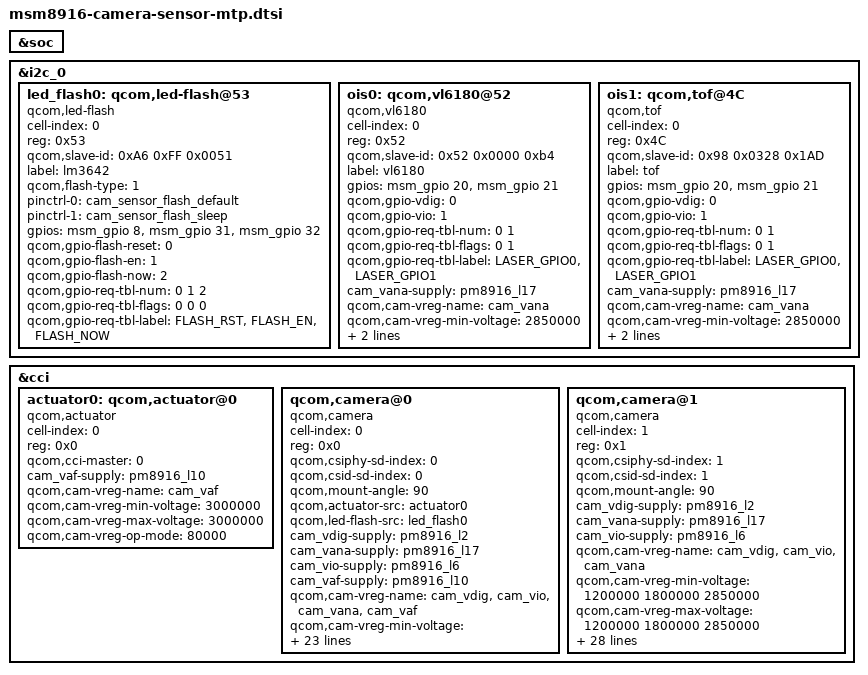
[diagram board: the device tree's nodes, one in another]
/*
 * Copyright (c) 2014, The Linux Foundation. All rights reserved.
 *
 * This program is free software; you can redistribute it and/or modify
 * it under the terms of the GNU General Public License version 2 and
 * only version 2 as published by the Free Software Foundation.
 *
 * This program is distributed in the hope that it will be useful,
 * but WITHOUT ANY WARRANTY; without even the implied warranty of
 * MERCHANTABILITY or FITNESS FOR A PARTICULAR PURPOSE.  See the
 * GNU General Public License for more details.
 */

&soc {
};

&i2c_0 {
//ASUS_BSP: Sam: flash driver i2c +++
	led_flash0: qcom,led-flash@53{
			cell-index = <0>;
			reg = <0x53>;
			qcom,slave-id = <0xA6 0xFF 0x0051>;
			compatible = "qcom,led-flash";
			label = "lm3642";
			//qcom,flash-name = "lm3642";
			qcom,flash-type = <1>;
			//qcom,enable_pinctrl;
			pinctrl-names = "cam_flash_default", "cam_flash_suspend";
			pinctrl-0 = <&cam_sensor_flash_default>;
			pinctrl-1 = <&cam_sensor_flash_sleep>;
			gpios = <&msm_gpio 8 0>,
				<&msm_gpio 31 0>,
				<&msm_gpio 32 0>;
			qcom,gpio-flash-reset = <0>;
			qcom,gpio-flash-en = <1>;
			qcom,gpio-flash-now = <2>;
			qcom,gpio-req-tbl-num = <0 1 2>;
			qcom,gpio-req-tbl-flags = <0 0 0>;
			qcom,gpio-req-tbl-label = "FLASH_RST",
				"FLASH_EN",
				"FLASH_NOW";
	};
//ASUS_BSP: Sam: flash driver i2c ---

//ASUS_BSP: Sam: laser driver i2c +++
       ois0: qcom,vl6180@52 {
		   cell-index = <0>;
		   reg = <0x52>;
		   qcom,slave-id = <0x52 0x0000 0xb4>;
		   compatible = "qcom,vl6180";
		   label = "vl6180";
/*
		   pinctrl-names = "laser_focus_default", "laser_focus_suspend";
		   pinctrl-0 = <&cam_sensor_laser_focus_gpio0_default &cam_sensor_laser_focus_gpio1_default >;
		   pinctrl-1 = <&cam_sensor_laser_focus_gpio0_sleep &cam_sensor_laser_focus_gpio1_sleep>;
*/
		   gpios = <&msm_gpio 20 0>,
				   <&msm_gpio 21 0>;//113 interrupt
		   qcom,gpio-vdig = <0>;
		   qcom,gpio-vio = <1>;
		   qcom,gpio-req-tbl-num = <0 1>;
		   qcom,gpio-req-tbl-flags = <0 1>;//GPIO0 pin configured as input, pull up, software not do anything with it
		   qcom,gpio-req-tbl-label = "LASER_GPIO0",
									 "LASER_GPIO1";
		   cam_vana-supply = <&pm8916_l17>;
		   qcom,cam-vreg-name = "cam_vana";
		   qcom,cam-vreg-min-voltage = <2850000>;
		   qcom,cam-vreg-max-voltage = <2850000>;
		   qcom,cam-vreg-op-mode = <80000>;
       };
//ASUS_BSP: Sam: laser driver i2c ---

		ois1: qcom,tof@4C {
			cell-index = <0>;
			reg = <0x4C>;
			qcom,slave-id = <0x98 0x0328 0x1AD>;
			compatible = "qcom,tof";
			label = "tof";
/*
		   pinctrl-names = "laser_focus_default", "laser_focus_suspend";
		   pinctrl-0 = <&cam_sensor_laser_focus_gpio0_default &cam_sensor_laser_focus_gpio1_default >;
		   pinctrl-1 = <&cam_sensor_laser_focus_gpio0_sleep &cam_sensor_laser_focus_gpio1_sleep>;
*/
		   gpios = <&msm_gpio 20 0>,
				   <&msm_gpio 21 0>;//113 interrupt
		   qcom,gpio-vdig = <0>;
		   qcom,gpio-vio = <1>;
		   qcom,gpio-req-tbl-num = <0 1>;
		   qcom,gpio-req-tbl-flags = <0 1>;//GPIO0 pin configured as input, pull up, software not do anything with it
		   qcom,gpio-req-tbl-label = "LASER_GPIO0",
									 "LASER_GPIO1";
		   cam_vana-supply = <&pm8916_l17>;
		   qcom,cam-vreg-name = "cam_vana";
		   qcom,cam-vreg-min-voltage = <2850000>;
		   qcom,cam-vreg-max-voltage = <2850000>;
		   qcom,cam-vreg-op-mode = <80000>;
		};
};

&cci {

	actuator0: qcom,actuator@0 {
		cell-index = <0>;
		reg = <0x0>;
		compatible = "qcom,actuator";
		qcom,cci-master = <0>;
		cam_vaf-supply = <&pm8916_l10>;
		qcom,cam-vreg-name = "cam_vaf";
		qcom,cam-vreg-min-voltage = <3000000>;
		qcom,cam-vreg-max-voltage = <3000000>;
		qcom,cam-vreg-op-mode = <80000>;
	};



/*
	eeprom0: qcom,eeprom@20 {
		cell-index = <0>;
		reg = <0x20>;
		qcom,eeprom-name = "sonyimx135";
		compatible = "qcom,eeprom";
		qcom,slave-addr = <0x20>;
		qcom,cci-master = <0>;
		qcom,num-blocks = <16>;

		qcom,page0 = <1 0x3b02 2 0x10 1 5>;
		qcom,pageen0 = <1 0x3b00 2 0x01 1 5>;
		qcom,poll0 = <1 0x3b01 2 0x01 1 5>;
		qcom,mem0 = <8 0x3b04 2 0 1 0>;

		qcom,page1 = <1 0x3b02 2 0x0F 1 5>;
		qcom,pageen1 = <1 0x3b00 2 0x01 1 5>;
		qcom,poll1 = <1 0x3b01 2 0x01 1 5>;
		qcom,mem1 = <8 0x3b04 2 0 1 0>;

		qcom,page2 = <1 0x3b02 2 0x0E 1 5>;
		qcom,pageen2 = <1 0x3b00 2 0x01 1 5>;
		qcom,poll2 = <1 0x3b01 2 0x01 1 5>;
		qcom,mem2 = <8 0x3b04 2 0 1 0>;

		qcom,page3 = <1 0x3b02 2 0x0D 1 5>;
		qcom,pageen3 = <1 0x3b00 2 0x01 1 5>;
		qcom,poll3 = <1 0x3b01 2 0x01 1 5>;
		qcom,mem3 = <8 0x3b04 2 0 1 0>;

		qcom,page4 = <1 0x3b02 2 0x12 1 5>;
		qcom,pageen4 = <1 0x3b00 2 0x01 1 5>;
		qcom,poll4 = <1 0x3b01 2 0x01 1 5>;
		qcom,mem4 = <7 0x3b09 2 0 1 0>;

		qcom,page5 = <1 0x3b02 2 0x11 1 5>;
		qcom,pageen5 = <1 0x3b00 2 0x01 1 5>;
		qcom,poll5 = <1 0x3b01 2 0x01 1 5>;
		qcom,mem5 = <7 0x3b09 2 0 1 0>;

		qcom,page6 = <1 0x3b02 2 0x10 1 5>;
		qcom,pageen6 = <1 0x3b00 2 0x01 1 5>;
		qcom,poll6 = <1 0x3b01 2 0x01 1 5>;
		qcom,mem6 = <7 0x3b09 2 0 1 0>;

		qcom,page7 = <1 0x3b02 2 0x09 1 5>;
		qcom,pageen7 = <1 0x3b00 2 0x01 1 5>;
		qcom,poll7 = <1 0x3b01 2 0x01 1 5>;
		qcom,mem7 = <7 0x3b09 2 0 1 0>;

		qcom,page8 = <1 0x3b02 2 0x01 1 5>;
		qcom,pageen8 = <1 0x3b00 2 0x01 1 5>;
		qcom,poll8 = <1 0x3b01 2 0x01 1 5>;
		qcom,mem8 = <64 0x3b04 2 0 1 0>;

		qcom,page9 = <1 0x3b02 2 0x02 1 5>;
		qcom,pageen9 = <1 0x3b00 2 0x01 1 5>;
		qcom,poll9 = <1 0x3b01 2 0x01 1 5>;
		qcom,mem9 = <64 0x3b04 2 0 1 0>;

		qcom,page10 = <1 0x3b02 2 0x03 1 5>;
		qcom,pageen10 = <1 0x3b00 2 0x01 1 5>;
		qcom,poll10 = <1 0x3b01 2 0x01 1 5>;
		qcom,mem10 = <64 0x3b04 2 0 1 0>;

		qcom,page11 = <1 0x3b02 2 0x04 1 5>;
		qcom,pageen11 = <1 0x3b00 2 0x01 1 5>;
		qcom,poll11 = <1 0x3b01 2 0x01 1 5>;
		qcom,mem11 = <64 0x3b04 2 0 1 0>;

		qcom,page12 = <1 0x3b02 2 0x05 1 5>;
		qcom,pageen12 = <1 0x3b00 2 0x01 1 5>;
		qcom,poll12 = <1 0x3b01 2 0x01 1 5>;
		qcom,mem12 = <64 0x3b04 2 0 1 0>;

		qcom,page13 = <1 0x3b02 2 0x06 1 5>;
		qcom,pageen13 = <1 0x3b00 2 0x01 1 5>;
		qcom,poll13 = <1 0x3b01 2 0x01 1 5>;
		qcom,mem13 = <64 0x3b04 2 0 1 0>;

		qcom,page14 = <1 0x3b02 2 0x07 1 5>;
		qcom,pageen14 = <1 0x3b00 2 0x01 1 5>;
		qcom,poll14 = <1 0x3b01 2 0x01 1 5>;
		qcom,mem14 = <64 0x3b04 2 0 1 0>;

		qcom,page15 = <1 0x3b02 2 0x08 1 5>;
		qcom,pageen15 = <1 0x3b00 2 0x01 1 5>;
		qcom,poll15 = <1 0x3b01 2 0x01 1 5>;
		qcom,mem15 = <56 0x3b04 2 0 1 0>;

		cam_vdig-supply = <&pm8916_s4>;
		cam_vio-supply = <&pm8916_l17>;
		cam_vana-supply = <&pm8916_l6>;
		qcom,cam-vreg-name = "cam_vdig", "cam_vio", "cam_vana";
		qcom,cam-vreg-min-voltage = <2100000 0 2850000 2800000>;
		qcom,cam-vreg-max-voltage = <2100000 0 2850000 2800000>;
		qcom,cam-vreg-op-mode = <200000 0 80000 100000>;
		pinctrl-names = "cam_default", "cam_suspend";
		pinctrl-0 = <&cam_sensor_mclk0_default &cam_sensor_rear_default>;
		pinctrl-1 = <&cam_sensor_mclk0_sleep &cam_sensor_rear_sleep>;
		qcom,gpio-no-mux = <0>;
		gpios = <&msm_gpio 26 0>,
			<&msm_gpio 35 0>,
			<&msm_gpio 34 0>;
		qcom,gpio-reset = <1>;
		qcom,gpio-standby = <2>;
		qcom,gpio-req-tbl-num = <0 1 2>;
		qcom,gpio-req-tbl-flags = <1 0 0>;
		qcom,gpio-req-tbl-label = "CAMIF_MCLK",
			"CAM_RESET1",
			"CAM_STANDBY";
		qcom,gpio-set-tbl-num = <1 1>;
		qcom,gpio-set-tbl-flags = <0 2>;
		qcom,gpio-set-tbl-delay = <1000 4000>;
		qcom,csi-lane-assign = <0x4320>;
		qcom,csi-lane-mask = <0x3>;
		qcom,cam-power-seq-type = "sensor_vreg", "sensor_vreg", "sensor_vreg",
			"sensor_gpio", "sensor_gpio" , "sensor_clk";
		qcom,cam-power-seq-val = "cam_vdig", "cam_vana", "cam_vio",
			"sensor_gpio_reset", "sensor_gpio_standby","sensor_cam_mclk";
		qcom,cam-power-seq-cfg-val = <1 1 1 1 1 24000000>;
		qcom,cam-power-seq-delay = <1 1 1 30 30 5>;
	};

	qcom,camera@78 {
		compatible = "ovti,ov5645";
		reg = <0x78 0x0>;
		qcom,slave-id = <0x78 0x300a 0x5645>;
		qcom,csiphy-sd-index = <1>;
		qcom,csid-sd-index = <1>;
		qcom,mount-angle = <90>;
		qcom,sensor-name = "ov5645";
		cam_vdig-supply = <&pm8916_s4>;
		cam_vana-supply = <&pm8916_l17>;
		cam_vio-supply = <&pm8916_l6>;
		qcom,cam-vreg-name = "cam_vdig", "cam_vio", "cam_vana";
		qcom,cam-vreg-min-voltage = <2100000 0 2850000>;
		qcom,cam-vreg-max-voltage = <2100000 0 2850000>;
		qcom,cam-vreg-op-mode = <200000 0 80000>;
		pinctrl-names = "cam_default", "cam_suspend";
		pinctrl-0 = <&cam_sensor_mclk1_default &cam_sensor_front_default>;
		pinctrl-1 = <&cam_sensor_mclk1_sleep &cam_sensor_front_sleep>;
		gpios = <&msm_gpio 27 0>,
			<&msm_gpio 28 0>,
			<&msm_gpio 33 0>;
		qcom,gpio-reset = <1>;
		qcom,gpio-standby = <2>;
		qcom,gpio-req-tbl-num = <0 1 2>;
		qcom,gpio-req-tbl-flags = <1 0 0>;
		qcom,gpio-req-tbl-label = "CAMIF_MCLK",
					"CAM_RESET",
					"CAM_STANDBY";
		qcom,gpio-set-tbl-num = <1 1>;
		qcom,gpio-set-tbl-flags = <0 2>;
		qcom,gpio-set-tbl-delay = <1000 4000>;
		qcom,csi-lane-assign = <0x4320>;
		qcom,csi-lane-mask = <0x3>;
		qcom,sensor-position = <1>;
		qcom,sensor-mode = <0>;
		qcom,cci-master = <0>;
		qcom,mclk-23880000;
		clocks = <&clock_gcc clk_mclk1_clk_src>,
				<&clock_gcc clk_gcc_camss_mclk1_clk>;
		clock-names = "cam_src_clk", "cam_clk";
	};
*/
//ASUS_BSP Stimber_Hsueh "Mini-porting for rear camera" +++
	qcom,camera@0 {
		cell-index = <0>;
		compatible = "qcom,camera";
		reg = <0x0>;
		qcom,csiphy-sd-index = <0>;
		qcom,csid-sd-index = <0>;
		qcom,mount-angle = <90>;
		qcom,actuator-src = <&actuator0>;
		qcom,led-flash-src = <&led_flash0>;
		cam_vdig-supply = <&pm8916_l2>;
		cam_vana-supply = <&pm8916_l17>;
		cam_vio-supply = <&pm8916_l6>;
		cam_vaf-supply = <&pm8916_l10>;
		qcom,cam-vreg-name = "cam_vdig", "cam_vio", "cam_vana",
							"cam_vaf";
		qcom,cam-vreg-min-voltage = <1200000 1800000 2850000 3000000>;
		qcom,cam-vreg-max-voltage = <1200000 1800000 2850000 3000000>;
		qcom,cam-vreg-op-mode = <200000 0 80000 100000>;
		pinctrl-names = "cam_default", "cam_suspend";
		pinctrl-0 = <&cam_sensor_mclk0_default &cam_sensor_rear_default>;
		pinctrl-1 = <&cam_sensor_mclk0_sleep &cam_sensor_rear_sleep>;
		gpios = <&msm_gpio 26 0>,
				<&msm_gpio 121 0>,
				<&msm_gpio 120 0>,
				<&msm_gpio 34 0>;
		qcom,gpio-vana = <1>;
		qcom,gpio-vdig = <2>;
		qcom,gpio-reset = <3>;
		qcom,gpio-req-tbl-num = <0 1 2 3>;
		qcom,gpio-req-tbl-flags = <1 0 0 0>;
		qcom,gpio-req-tbl-label = "CAMIF_MCLK",
			"INT_CAM_2V8_EN",
			"CAM_1V2_EN",
			"CAM_RESET1";
		qcom,sensor-position = <0>;
		qcom,sensor-mode = <0>;
		qcom,cci-master = <0>;
		qcom,mclk-23880000;
		status = "ok";
		clocks = <&clock_gcc clk_mclk0_clk_src>,
				<&clock_gcc clk_gcc_camss_mclk0_clk>;
		clock-names = "cam_src_clk", "cam_clk";
	};
//ASUS_BSP Stimber_Hsueh "Mini-porting for rear camera" ---
	qcom,camera@1 {
        cell-index = <1>;
        compatible = "qcom,camera";
        reg = <0x1>;
        qcom,csiphy-sd-index = <1>;
        qcom,csid-sd-index = <1>;
        qcom,mount-angle = <90>;
        cam_vdig-supply = <&pm8916_l2>;
        cam_vana-supply = <&pm8916_l17>;
        cam_vio-supply = <&pm8916_l6>;
        qcom,cam-vreg-name = "cam_vdig", "cam_vio", "cam_vana";
        qcom,cam-vreg-min-voltage = <1200000 1800000 2850000>;
        qcom,cam-vreg-max-voltage =<1200000 1800000 2850000>;
        qcom,cam-vreg-op-mode = <200000 0 80000>;
        pinctrl-names = "cam_default", "cam_suspend";
        pinctrl-0 = <&cam_sensor_mclk1_default &cam_sensor_front_default &cam_sensor_front_id_default>;
        pinctrl-1 = <&cam_sensor_mclk1_sleep &cam_sensor_front_sleep &cam_sensor_front_id_sleep>;
        gpios = <&msm_gpio 27 0>,
            <&msm_gpio 121 0>,
            <&msm_gpio 120 0>,
            <&msm_gpio 33 0>,
            <&msm_gpio 28 0>,
            <&msm_gpio 50 0>;
        qcom,gpio-custom1 = <5>;
        qcom,gpio-reset = <4>;
        qcom,gpio-standby = <3>;
        qcom,gpio-vdig = <2>;
        qcom,gpio-vana = <1>;
        qcom,gpio-req-tbl-num = <0 1 2 3 4 5>;
        qcom,gpio-req-tbl-flags = <1 0 0 0 0 1>;
        qcom,gpio-req-tbl-label = "CAMIF_MCLK",
                    "INT_CAM_2V8_EN",
                    "CAM_1V2_EN",
            "CAM_STANDBY",
            "CAM_RESET",
            "CAM_ID";
        qcom,csi-lane-assign = <0x4320>;
        qcom,csi-lane-mask = <0x3>;
        qcom,sensor-position = <1>;
        qcom,sensor-mode = <0>;
        qcom,cci-master = <0>;
        qcom,mclk-23880000;
        status = "ok";
        clocks = <&clock_gcc clk_mclk1_clk_src>,
                <&clock_gcc clk_gcc_camss_mclk1_clk>;
        clock-names = "cam_src_clk", "cam_clk";
	};
/*	qcom,camera@1 {
		cell-index = <1>;
		compatible = "qcom,camera";
		reg = <0x1>;
		qcom,csiphy-sd-index = <1>;
		qcom,csid-sd-index = <1>;
		qcom,mount-angle = <90>;
		cam_vdig-supply = <&pm8916_l2>;
		cam_vana-supply = <&pm8916_l17>;
		cam_vio-supply = <&pm8916_l16>;
		qcom,cam-vreg-name = "cam_vdig", "cam_vio", "cam_vana";
		qcom,cam-vreg-min-voltage = <1200000 1800000 2850000>;
		qcom,cam-vreg-max-voltage =<1200000 1800000 2850000>;
		qcom,cam-vreg-op-mode = <200000 0 80000 100000>;
		pinctrl-names = "cam_default", "cam_suspend";
		pinctrl-0 = <&cam_sensor_mclk1_default &cam_sensor_front_default>;
		pinctrl-1 = <&cam_sensor_mclk1_sleep &cam_sensor_front_sleep>;
		gpios = <&msm_gpio 27 0>,
			<&msm_gpio 34 0>,
			<&msm_gpio 116 0>,
			<&msm_gpio 33 0>,
			<&msm_gpio 16 0>,
			<&msm_gpio 115 0>;
		qcom,gpio-custom1 = <5>;
		qcom,gpio-reset = <4>;
		qcom,gpio-standby = <3>;
		qcom,gpio-vdig = <2>;
		qcom,gpio-vana = <1>;
		qcom,gpio-req-tbl-num = <0 1 2 3 4 5>;
		qcom,gpio-req-tbl-flags = <1 0 0 0 0 0>;
		qcom,gpio-req-tbl-label = "CAMIF_MCLK",
					"INT_CAM_2V8_EN",
					"CAM_1V2_EN",
			"CAM_STANDBY",
			"CAM_RESET",
			"CAM_1V8_EN";
		qcom,csi-lane-assign = <0x4320>;
		qcom,csi-lane-mask = <0x3>;
		qcom,sensor-position = <1>;
		qcom,sensor-mode = <0>;
		qcom,cci-master = <0>;
		qcom,mclk-23880000;
		status = "ok";
		clocks = <&clock_gcc clk_mclk1_clk_src>,
				<&clock_gcc clk_gcc_camss_mclk1_clk>;
		clock-names = "cam_src_clk", "cam_clk";
	};*/
};
